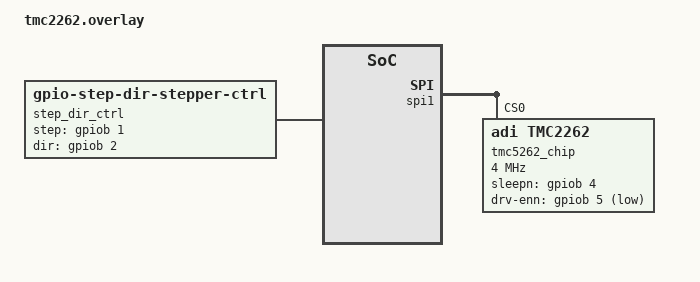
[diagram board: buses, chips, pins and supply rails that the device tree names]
/*
 * SPDX-FileCopyrightText: Copyright (c) 2026 Analog Devices, Inc.
 * SPDX-License-Identifier: Apache-2.0
 */

/*
 * TMC2262: STEP/DIR only. The chip is configured over SPI, the steps are generated by the
 * generic GPIO STEP/DIR motion controller, which takes the pulse timing from the
 * stepper-driver child of the chip.
 */

/ {
	aliases {
		stepper-chip = &tmc5262_chip;
		stepper-driver = &tmc_driver;
		stepper-sensor = &tmc_sensor;
		stepper-ctrl = &step_dir_ctrl;
	};

	step_dir_ctrl: step-dir-controller {
		compatible = "zephyr,gpio-step-dir-stepper-ctrl";
		step-gpios = <&gpiob 1 GPIO_ACTIVE_HIGH>;
		dir-gpios = <&gpiob 2 GPIO_ACTIVE_HIGH>;
		stepper-driver = <&tmc_driver>;
	};
};

&spi1 {
	tmc5262_chip: tmc2262@0 {
		compatible = "adi,tmc2262";
		reg = <0>;
		spi-max-frequency = <DT_FREQ_M(4)>;
		sleepn-gpios = <&gpiob 4 GPIO_ACTIVE_HIGH>;
		drv-enn-gpios = <&gpiob 5 GPIO_ACTIVE_LOW>;

		/* 6 A peak range, run at about 50 percent */
		current-range-ma = <6000>;
		irun = <127>;
		ihold = <32>;

		tmc_sensor: sensor {
			compatible = "adi,tmc5262-sensor";
		};

		tmc_driver: stepper-driver {
			compatible = "adi,tmc5262-stepper-driver";
			micro-step-res = <16>;
		};
	};
};
